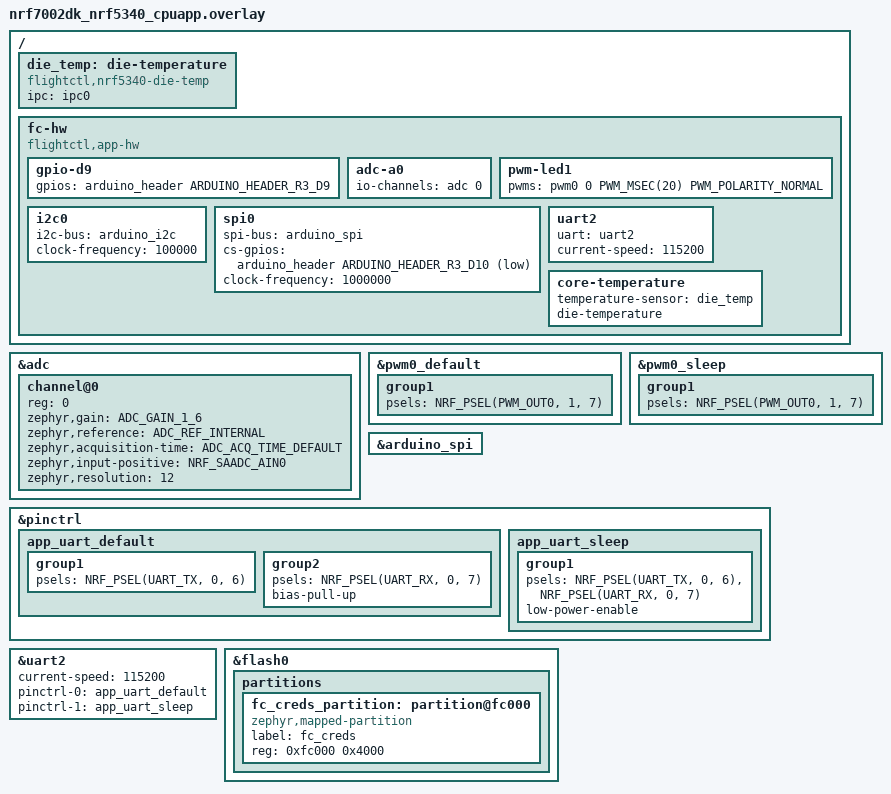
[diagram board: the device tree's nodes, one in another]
#include "nrf7002dk_ota_slots.dtsi"

&adc {
    #address-cells = <1>;
    #size-cells = <0>;
    channel@0 {
        reg = <0>;
        zephyr,gain = "ADC_GAIN_1_6";
        zephyr,reference = "ADC_REF_INTERNAL";
        zephyr,acquisition-time = <ADC_ACQ_TIME_DEFAULT>;
        zephyr,input-positive = <NRF_SAADC_AIN0>;
        zephyr,resolution = <12>;
    };
};

/* PWM on the second green LED leaves the first LED under GPIO control. */
&pwm0_default {
    group1 { psels = <NRF_PSEL(PWM_OUT0, 1, 7)>; };
};
&pwm0_sleep {
    group1 { psels = <NRF_PSEL(PWM_OUT0, 1, 7)>; };
};

&arduino_spi { status = "okay"; };

/* UARTE2 on A2/A3 avoids the console, the network core's forwarded
 * UART pins and the serial instance shared with the header's I2C bus. */
&pinctrl {
    app_uart_default: app_uart_default {
        group1 { psels = <NRF_PSEL(UART_TX, 0, 6)>; };
        group2 {
            psels = <NRF_PSEL(UART_RX, 0, 7)>;
            bias-pull-up;
        };
    };
    app_uart_sleep: app_uart_sleep {
        group1 {
            psels = <NRF_PSEL(UART_TX, 0, 6)>, <NRF_PSEL(UART_RX, 0, 7)>;
            low-power-enable;
        };
    };
};

&uart2 {
    status = "okay";
    current-speed = <115200>;
    pinctrl-0 = <&app_uart_default>;
    pinctrl-1 = <&app_uart_sleep>;
    pinctrl-names = "default", "sleep";
};

&flash0 {
    partitions {
        fc_creds_partition: partition@fc000 {
            compatible = "zephyr,mapped-partition";
            label = "fc_creds";
            reg = <0xfc000 0x4000>;
        };
    };
};

/ {
    die_temp: die-temperature {
        compatible = "flightctl,nrf5340-die-temp";
        ipc = <&ipc0>;
    };

    fc-hw {
        compatible = "flightctl,app-hw";
        gpio-d9 { gpios = <&arduino_header ARDUINO_HEADER_R3_D9 GPIO_ACTIVE_HIGH>; };
        adc-a0 { io-channels = <&adc 0>; };
        pwm-led1 { pwms = <&pwm0 0 PWM_MSEC(20) PWM_POLARITY_NORMAL>; };
        i2c0 { i2c-bus = <&arduino_i2c>; clock-frequency = <100000>; };
        spi0 {
            spi-bus = <&arduino_spi>;
            cs-gpios = <&arduino_header ARDUINO_HEADER_R3_D10 GPIO_ACTIVE_LOW>;
            clock-frequency = <1000000>;
        };
        uart2 { uart = <&uart2>; current-speed = <115200>; };
        core-temperature {
            temperature-sensor = <&die_temp>;
            die-temperature;
        };
    };
};
